# MB9AF12xK register map
File version: 1.0
Registers are 32-bit, read-write, reset 0x0 unless marked. A register's access mark holds for its fields unless they carry their own. Offsets are from the block's base; [hi:lo] are bit positions; {n}, {i} and the like mark numbered series.

## LVD — peripheral LVD
Base 0x40035000
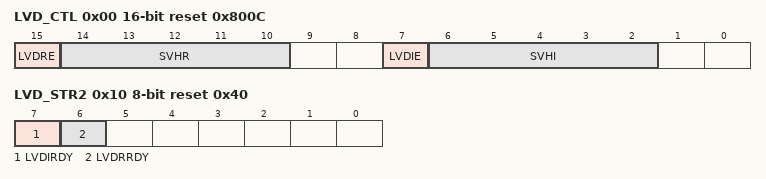
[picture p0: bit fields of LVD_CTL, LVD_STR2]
0x00 LVD_CTL 16-bit reset 0x800C
  [15] LVDRE, [14:10] SVHR, [7] LVDIE, [6:2] SVHI
0x04 LVD_STR 8-bit ro
  [7] LVDIR
0x08 LVD_CLR 8-bit reset 0x80
  [7] LVDCL
0x0C LVD_RLR reset 0x1
  [31:0] LVDLCK
0x10 LVD_STR2 8-bit ro reset 0x40
  [7] LVDIRDY, [6] LVDRRDY

## DS — peripheral DS
Base 0x40035100
0x00 REG_CTL 8-bit reset 0x4
  [2:1] ISUBSEL
0x04 RCK_CTL 8-bit reset 0x1
  [0] RTCCKE
0x700 PMD_CTL 8-bit
  [0] RTCE

## MFS0 — peripheral MFS0
Base 0x40038000
Same registers: MFS1 0x40038100, MFS3 0x40038300, MFS5 0x40038500
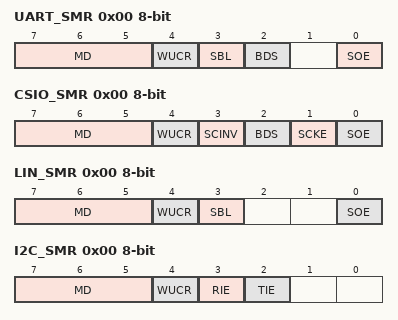
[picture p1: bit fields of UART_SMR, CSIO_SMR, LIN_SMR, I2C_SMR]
0x00 UART_SMR 8-bit (UART view)
  [7:5] MD, [4] WUCR, [3] SBL, [2] BDS, [0] SOE
0x00 CSIO_SMR 8-bit (CSIO view)
  [7:5] MD, [4] WUCR, [3] SCINV, [2] BDS, [1] SCKE, [0] SOE
0x00 LIN_SMR 8-bit (LIN view)
  [7:5] MD, [4] WUCR, [3] SBL, [0] SOE
0x00 I2C_SMR 8-bit (I2C view)
  [7:5] MD, [4] WUCR, [3] RIE, [2] TIE
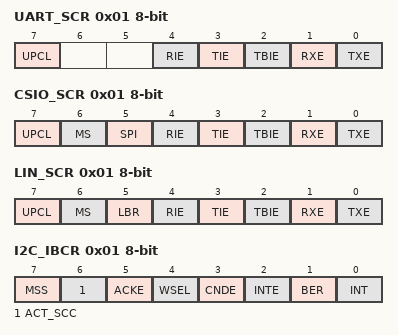
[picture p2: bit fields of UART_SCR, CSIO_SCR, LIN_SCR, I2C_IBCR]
0x01 UART_SCR 8-bit (UART view)
  [7] UPCL, [4] RIE, [3] TIE, [2] TBIE, [1] RXE, [0] TXE
0x01 CSIO_SCR 8-bit (CSIO view)
  [7] UPCL, [6] MS, [5] SPI, [4] RIE, [3] TIE, [2] TBIE, [1] RXE, [0] TXE
0x01 LIN_SCR 8-bit (LIN view)
  [7] UPCL, [6] MS, [5] LBR, [4] RIE, [3] TIE, [2] TBIE, [1] RXE, [0] TXE
0x01 I2C_IBCR 8-bit (I2C view)
  [7] MSS, [6] ACT_SCC, [5] ACKE, [4] WSEL, [3] CNDE, [2] INTE, [1] BER ro, [0] INT
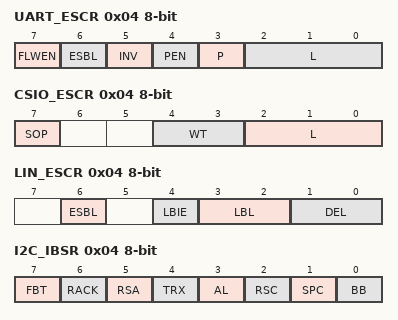
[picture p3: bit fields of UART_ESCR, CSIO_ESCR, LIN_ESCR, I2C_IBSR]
0x04 UART_ESCR 8-bit (UART view)
  [7] FLWEN, [6] ESBL, [5] INV, [4] PEN, [3] P, [2:0] L
0x04 CSIO_ESCR 8-bit (CSIO view)
  [7] SOP, [4:3] WT, [2:0] L
0x04 LIN_ESCR 8-bit (LIN view)
  [6] ESBL, [4] LBIE, [3:2] LBL, [1:0] DEL
0x04 I2C_IBSR 8-bit (I2C view)
  [7] FBT ro, [6] RACK ro, [5] RSA ro, [4] TRX ro, [3] AL ro, [2] RSC, [1] SPC, [0] BB ro
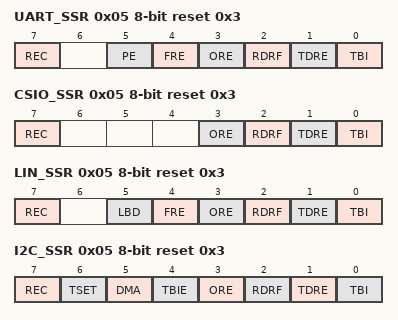
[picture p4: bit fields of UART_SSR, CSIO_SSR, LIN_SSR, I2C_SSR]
0x05 UART_SSR 8-bit reset 0x3 (UART view)
  [7] REC, [5] PE ro, [4] FRE ro, [3] ORE ro, [2] RDRF ro, [1] TDRE ro, [0] TBI ro
0x05 CSIO_SSR 8-bit reset 0x3 (CSIO view)
  [7] REC, [3] ORE ro, [2] RDRF ro, [1] TDRE ro, [0] TBI ro
0x05 LIN_SSR 8-bit reset 0x3 (LIN view)
  [7] REC, [5] LBD, [4] FRE ro, [3] ORE ro, [2] RDRF ro, [1] TDRE ro, [0] TBI ro
0x05 I2C_SSR 8-bit reset 0x3 (I2C view)
  [7] REC, [6] TSET, [5] DMA, [4] TBIE, [3] ORE ro, [2] RDRF ro, [1] TDRE ro, [0] TBI ro
0x08 UART_RDR 16-bit ro (reset mask 0x1FF) (UART view)
0x08 UART_TDR 16-bit wo reset 0x1FF (reset mask 0x1FF) (UART view)
0x08 CSIO_RDR 16-bit ro (reset mask 0x1FF) (CSIO view)
0x08 CSIO_TDR 16-bit wo reset 0x1FF (reset mask 0x1FF) (CSIO view)
0x08 LIN_RDR 16-bit ro (reset mask 0xFF) (LIN view)
0x08 LIN_TDR 16-bit wo reset 0xFF (reset mask 0xFF) (LIN view)
0x08 I2C_RDR 16-bit ro (reset mask 0xFF) (I2C view)
0x08 I2C_TDR 16-bit wo reset 0xFF (reset mask 0xFF) (I2C view)
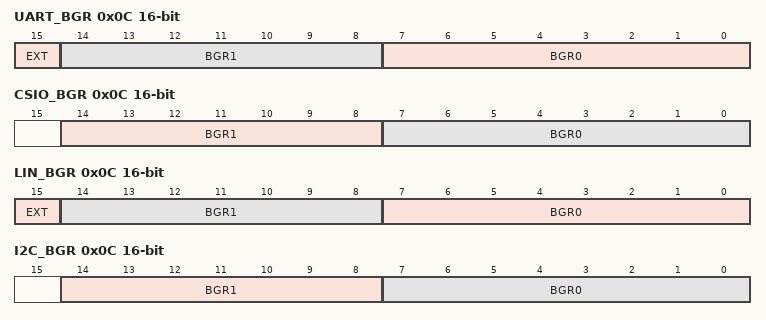
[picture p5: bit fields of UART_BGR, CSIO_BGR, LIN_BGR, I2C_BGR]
0x0C UART_BGR 16-bit (UART view)
  [15] EXT, [14:8] BGR1, [7:0] BGR0
0x0C CSIO_BGR 16-bit (CSIO view)
  [14:8] BGR1, [7:0] BGR0
0x0C LIN_BGR 16-bit (LIN view)
  [15] EXT, [14:8] BGR1, [7:0] BGR0
0x0C I2C_BGR 16-bit (I2C view)
  [14:8] BGR1, [7:0] BGR0
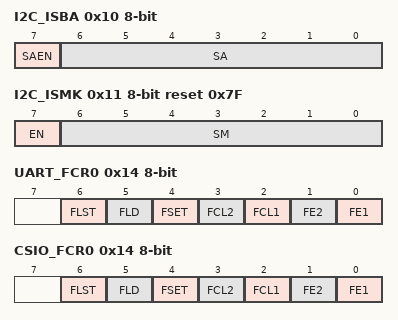
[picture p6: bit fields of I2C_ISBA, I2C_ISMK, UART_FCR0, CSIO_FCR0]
0x10 I2C_ISBA 8-bit (I2C view)
  [7] SAEN, [6:0] SA
0x11 I2C_ISMK 8-bit reset 0x7F (I2C view)
  [7] EN, [6:0] SM
0x14 UART_FCR0 8-bit (UART view)
  [6] FLST ro, [5] FLD, [4] FSET, [3] FCL2, [2] FCL1, [1] FE2, [0] FE1
0x14 CSIO_FCR0 8-bit (CSIO view)
  [6] FLST ro, [5] FLD, [4] FSET, [3] FCL2, [2] FCL1, [1] FE2, [0] FE1
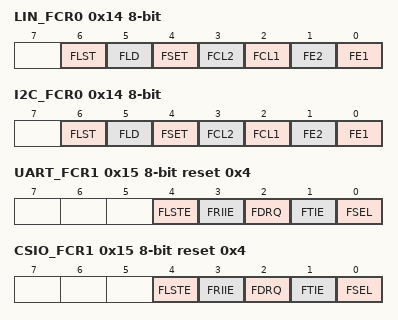
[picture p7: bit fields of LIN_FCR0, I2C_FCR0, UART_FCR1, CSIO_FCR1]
0x14 LIN_FCR0 8-bit (LIN view)
  [6] FLST ro, [5] FLD, [4] FSET, [3] FCL2, [2] FCL1, [1] FE2, [0] FE1
0x14 I2C_FCR0 8-bit (I2C view)
  [6] FLST ro, [5] FLD, [4] FSET, [3] FCL2, [2] FCL1, [1] FE2, [0] FE1
0x15 UART_FCR1 8-bit reset 0x4 (UART view)
  [4] FLSTE, [3] FRIIE, [2] FDRQ, [1] FTIE, [0] FSEL
0x15 CSIO_FCR1 8-bit reset 0x4 (CSIO view)
  [4] FLSTE, [3] FRIIE, [2] FDRQ, [1] FTIE, [0] FSEL
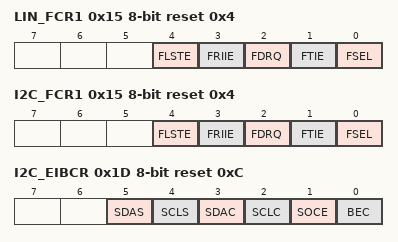
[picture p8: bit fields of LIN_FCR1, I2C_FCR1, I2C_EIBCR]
0x15 LIN_FCR1 8-bit reset 0x4 (LIN view)
  [4] FLSTE, [3] FRIIE, [2] FDRQ, [1] FTIE, [0] FSEL
0x15 I2C_FCR1 8-bit reset 0x4 (I2C view)
  [4] FLSTE, [3] FRIIE, [2] FDRQ, [1] FTIE, [0] FSEL
0x18 UART_FBYTE1 8-bit (UART view)
0x18 CSIO_FBYTE1 8-bit (CSIO view)
0x18 LIN_FBYTE1 8-bit (LIN view)
0x18 I2C_FBYTE1 8-bit (I2C view)
0x19 UART_FBYTE2 8-bit (UART view)
0x19 CSIO_FBYTE2 8-bit (CSIO view)
0x19 LIN_FBYTE2 8-bit (LIN view)
0x19 I2C_FBYTE2 8-bit (I2C view)
0x1D I2C_EIBCR 8-bit reset 0xC (I2C view)
  [5] SDAS, [4] SCLS, [3] SDAC, [2] SCLC, [1] SOCE, [0] BEC

## RTC — peripheral RTC
Base 0x4003B000
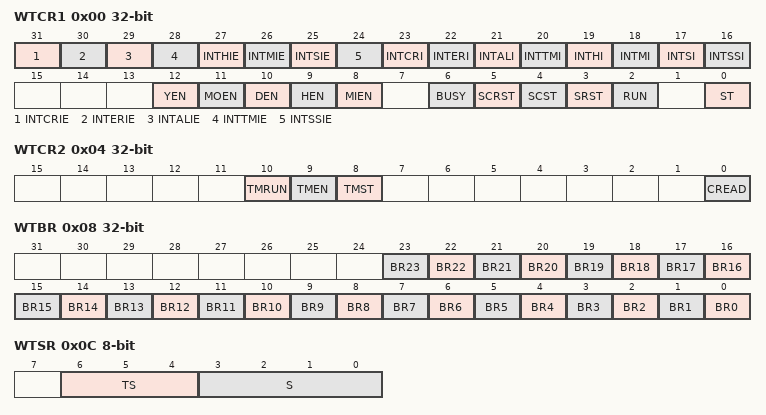
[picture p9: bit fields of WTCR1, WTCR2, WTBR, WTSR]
0x00 WTCR1
  [31] INTCRIE, [30] INTERIE, [29] INTALIE, [28] INTTMIE, [27] INTHIE, [26] INTMIE, [25] INTSIE, [24] INTSSIE, [23] INTCRI, [22] INTERI, [21] INTALI, [20] INTTMI, [19] INTHI, [18] INTMI, [17] INTSI, [16] INTSSI, [12] YEN, [11] MOEN, [10] DEN, [9] HEN, [8] MIEN, [6] BUSY ro, [5] SCRST, [4] SCST, [3] SRST, [2] RUN ro, [0] ST
0x04 WTCR2
  [10] TMRUN ro, [9] TMEN, [8] TMST, [0] CREAD
0x08 WTBR
  [n] BR{n} (n=0..23)
0x0C WTSR 8-bit
  [6:4] TS, [3:0] S
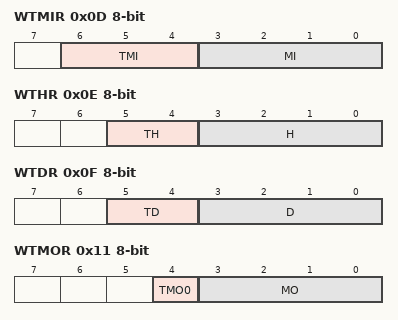
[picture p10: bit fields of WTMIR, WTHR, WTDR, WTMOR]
0x0D WTMIR 8-bit
  [6:4] TMI, [3:0] MI
0x0E WTHR 8-bit
  [5:4] TH, [3:0] H
0x0F WTDR 8-bit
  [5:4] TD, [3:0] D
0x10 WTDW 8-bit
  [2:0] DW
0x11 WTMOR 8-bit
  [4] TMO0, [3:0] MO
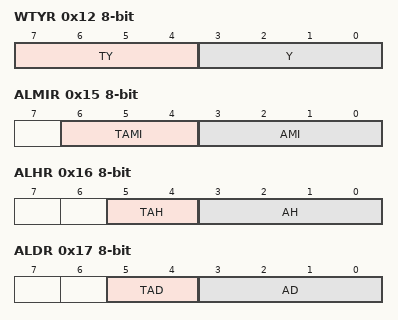
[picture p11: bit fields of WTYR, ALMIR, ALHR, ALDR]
0x12 WTYR 8-bit
  [7:4] TY, [3:0] Y
0x15 ALMIR 8-bit
  [6:4] TAMI, [3:0] AMI
0x16 ALHR 8-bit
  [5:4] TAH, [3:0] AH
0x17 ALDR 8-bit
  [5:4] TAD, [3:0] AD
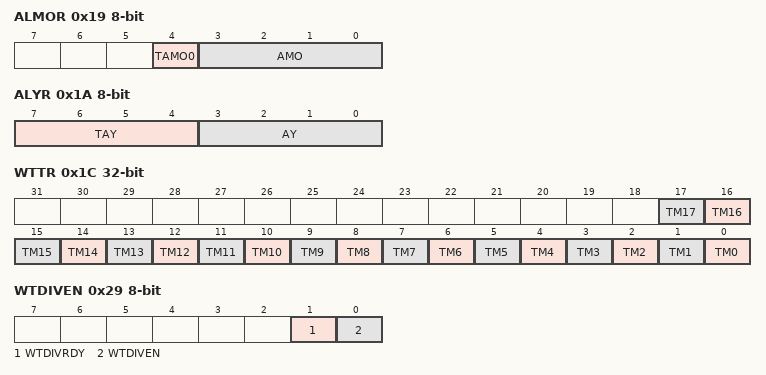
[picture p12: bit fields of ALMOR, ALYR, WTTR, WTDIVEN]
0x19 ALMOR 8-bit
  [4] TAMO0, [3:0] AMO
0x1A ALYR 8-bit
  [7:4] TAY, [3:0] AY
0x1C WTTR
  [n] TM{n} (n=0..17)
0x20 WTCLKS 8-bit
  [0] WTCLKS
0x21 WTCLKM 8-bit ro
  [1:0] WTCLKM
0x24 WTCAL 16-bit
  [9:0] WTCAL
0x26 WTCALEN 8-bit
  [0] WTCALEN
0x28 WTDIV 8-bit
  [3:0] WTDIV
0x29 WTDIVEN 8-bit
  [1] WTDIVRDY ro, [0] WTDIVEN
0x2C WTCALPRD 8-bit reset 0x13
  [5:0] WTCALPRD
0x30 WTCOSEL 8-bit
  [0] WTCOSEL

## Notices in the file
Licence Terms
FUJITSU SEMICONDUCTOR LIMITED (gLICENSORh) hereby grants and
you (gLICENSEEh) hereby accept a non transferable, non-exclusive
licence to use and copy the deliverables (gDeliverablesh) solely for
the purpose of; (i) developing LICENSEEfs development tools and
distributing such development tools to third parties; (ii) generating
derivative representations of the Deliverables to develop and debug
software for LICENSORfs targeted devices or device series identified
within the Deliverables, (together the gPurposeh) under the following
terms and conditions:
1. Ownership.
The Deliverables are the property of LICENSOR. LICENSEE acquires no
right, title or interest in the Deliverables other than the licence
rights granted herein.
2. Use.
LICENSEE shall only be permitted to use the Deliverables for the
Purpose. LICENSEE shall not reverse engineer, decompile or
disassemble the Deliverables, in whole or in part.
3. Copies.
All copies of the Deliverables must bear the same notice(s) contained
on the original copies of the Deliverables.
4. No Warranty.
THE DELIVERABLES ARE PROVIDED gAS ISh AND ANY EXPRESS, IMPLIED OR
STATUTORY WARRANTIES, INCLUDING, BUT NOT LIMITED TO, THE IMPLIED
WARRANTIES OF MERCHANTABILITY, SATISFACTORY QUALITY AND FITNESS FOR
A PARTICULAR PURPOSE ARE DISCLAIMED.
IN NO EVENT SHALL LICENSOR BE LIABLE FOR ANY DIRECT, INDIRECT,
INCIDENTAL, SPECIAL, EXEMPLARY, OR CONSEQUENTIAL DAMAGES HOWEVER CAUSED
AND ON ANY THEORY OF LIABILITY, WHETHER IN CONTRACT, STRICT LIABILITY,
OR TORT (INCLUDING NEGLIGENCE OR OTHERWISE) ARISING IN ANY WAY OUT OF
THE USE OF THE DELIVERABLES, EVEN IF ADVISED OF THE POSSIBILITY OF SUCH
DAMAGE.
LICENSEE EXPRESSLY ASSUMES ALL LIABILITIES AND RISKS, FOR USE OR
OPERATION OF THE DELIVERABLES.
5.In the event that LICENSEE receives early access to the Deliverables,
LICENSEE acknowledges and agrees that;
(a) notwithstanding the licence grants above, LICENSEE shall only be
permitted to use the Deliverables solely internally for evaluation and
providing feedback to LICENSOR;
(b) except with respect to the limited licence grants in 5(a), LICENSEE
shall be subject to all of the terms and conditions set out above; and
(c) the Deliverables are confidential information and LICENSEE shall
maintain in confidence the Deliverables and apply security measures no
less stringent than the measures that LICENSEE applies to its own like
information, but not less than a reasonable degree of care, to prevent
unauthorised disclosure and use of the Deliverables.
